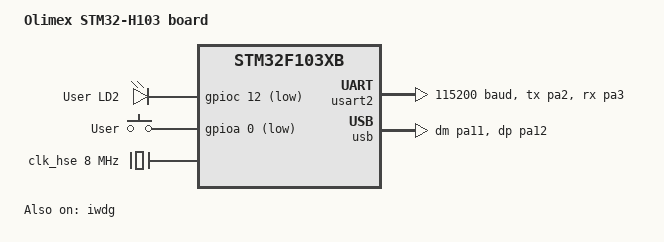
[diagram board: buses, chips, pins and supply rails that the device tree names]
/*
 * SPDX-License-Identifier: Apache-2.0
 * Copyright (c) 2020, Josep Puigdemont
 */

/dts-v1/;
#include <st/f1/stm32f103Xb.dtsi>
#include <st/f1/stm32f103r(8-b)tx-pinctrl.dtsi>
#include <zephyr/dt-bindings/input/input-event-codes.h>

/ {
	model = "Olimex STM32-H103 board";
	compatible = "olimex,stm32-h103";

	chosen {
		zephyr,console = &usart2;
		zephyr,shell-uart = &usart2;
		zephyr,sram = &sram0;
		zephyr,flash = &flash0;
	};

	leds {
		compatible = "gpio-leds";

		green_led_2: led_2 {
			gpios = <&gpioc 12 GPIO_ACTIVE_LOW>;
			label = "User LD2";
		};
	};

	gpio_keys {
		compatible = "gpio-keys";

		user_button: button {
			label = "User";
			gpios = <&gpioa 0 GPIO_ACTIVE_LOW>;
			zephyr,code = <INPUT_KEY_0>;
		};
	};

	aliases {
		led0 = &green_led_2;
		sw0 = &user_button;
		watchdog0 = &iwdg;
	};
};

&clk_hse {
	clock-frequency = <DT_FREQ_M(8)>;
	status = "okay";
};

&pll {
	mul = <9>;
	clocks = <&clk_hse>;
	status = "okay";
};

&rcc {
	clocks = <&pll>;
	clock-frequency = <DT_FREQ_M(72)>;
	ahb-prescaler = <1>;
	apb1-prescaler = <2>;
	apb2-prescaler = <1>;
	/* usbpre not set: USB clock = 72 / 1.5: 48MHz */
};

&usart1 {
	pinctrl-0 = <&usart1_tx_pa9 &usart1_rx_pa10>;
	pinctrl-names = "default";
	current-speed = <115200>;
	status = "disabled";
};

&usart2 {
	pinctrl-0 = <&usart2_tx_pa2 &usart2_rx_pa3>;
	pinctrl-names = "default";
	current-speed = <115200>;
	status = "okay";
};

&usart3 {
	pinctrl-0 = <&usart3_tx_remap1_pc10 &usart3_rx_remap1_pc11>;
	pinctrl-names = "default";
	current-speed = <115200>;
	status = "disabled";
};

&i2c1 {
	pinctrl-0 = <&i2c1_scl_pb6 &i2c1_sda_pb7>;
	pinctrl-names = "default";
	status = "disabled";
	clock-frequency = <I2C_BITRATE_FAST>;
};

&i2c2 {
	pinctrl-0 = <&i2c2_scl_pb10 &i2c2_sda_pb11>;
	pinctrl-names = "default";
	status = "disabled";
	clock-frequency = <I2C_BITRATE_FAST>;
};

&spi1 {
	pinctrl-0 = <&spi1_nss_master_pa4 &spi1_sck_master_pa5
		     &spi1_miso_master_pa6 &spi1_mosi_master_pa7>;
	pinctrl-names = "default";
	status = "disabled";
};

&spi2 {
	pinctrl-0 = <&spi2_nss_master_pb12 &spi2_sck_master_pb13
		     &spi2_miso_master_pb14 &spi2_mosi_master_pb15>;
	pinctrl-names = "default";
	status = "disabled";
};

&iwdg {
	status = "okay";
};

zephyr_udc0: &usb {
	pinctrl-0 = <&usb_dm_pa11 &usb_dp_pa12>;
	pinctrl-names = "default";
	disconnect-gpios = <&gpioc 11 GPIO_ACTIVE_LOW>;
};
